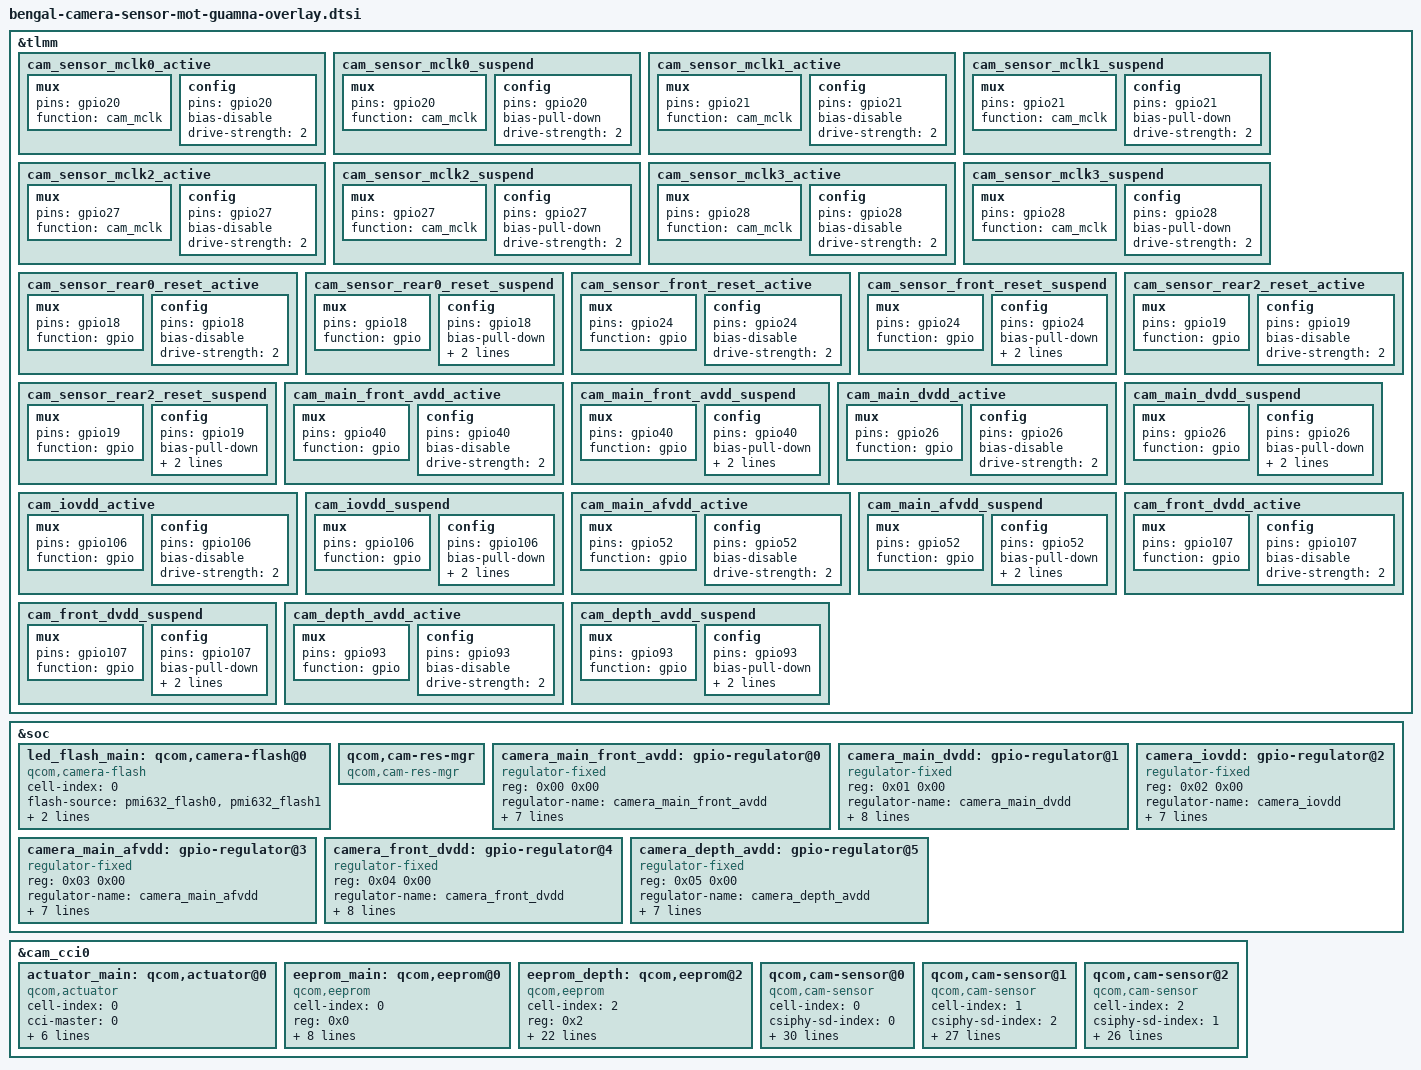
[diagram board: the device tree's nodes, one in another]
#include <dt-bindings/clock/qcom,gcc-bengal.h>

&tlmm {
	cam_sensor_mclk0_active: cam_sensor_mclk0_active {
		/* main mclk*/
		mux {
			pins = "gpio20";
			function = "cam_mclk";
		};

		config {
			pins = "gpio20";
			bias-disable;
			drive-strength = <2>;
		};
	};

	cam_sensor_mclk0_suspend: cam_sensor_mclk0_suspend {
		/* main mclk*/
		mux {
			pins = "gpio20";
			function = "cam_mclk";
		};

		config {
			pins = "gpio20";
			bias-pull-down;
			drive-strength = <2>;
		};
	};

	cam_sensor_mclk1_active: cam_sensor_mclk1_active {
		/* depth mclk*/
		mux {
			pins = "gpio21";
			function = "cam_mclk";
		};

		config {
			pins = "gpio21";
			bias-disable;
			drive-strength = <2>;
		};
	};

	cam_sensor_mclk1_suspend: cam_sensor_mclk1_suspend {
		/* depth mclk*/
		mux {
			pins = "gpio21";
			function = "cam_mclk";
		};

		config {
			pins = "gpio21";
			bias-pull-down;
			drive-strength = <2>;
		};
	};

	cam_sensor_mclk2_active: cam_sensor_mclk2_active {
		/* front mclk*/
		mux {
			pins = "gpio27";
			function = "cam_mclk";
		};

		config {
			pins = "gpio27";
			bias-disable;
			drive-strength = <2>;
		};
	};

	cam_sensor_mclk2_suspend: cam_sensor_mclk2_suspend {
		/* front mclk*/
		mux {
			pins = "gpio27";
			function = "cam_mclk";
		};

		config {
			pins = "gpio27";
			bias-pull-down;
			drive-strength = <2>;
		};
	};

	cam_sensor_mclk3_active: cam_sensor_mclk3_active {
		/* macro mclk*/
		mux {
			pins = "gpio28";
			function = "cam_mclk";
		};

		config {
			pins = "gpio28";
			bias-disable;
			drive-strength = <2>;
		};
	};

	cam_sensor_mclk3_suspend: cam_sensor_mclk3_suspend {
		/* macro mclk*/
		mux {
			pins = "gpio28";
			function = "cam_mclk";
		};

		config {
			pins = "gpio28";
			bias-pull-down;
			drive-strength = <2>;
		};
	};

	cam_sensor_rear0_reset_active: cam_sensor_rear0_reset_active {
		/* main reset*/
		mux {
			pins = "gpio18";
			function = "gpio";
		};

		config {
			pins = "gpio18";
			bias-disable; /* No PULL */
			drive-strength = <2>;
		};
	};

	cam_sensor_rear0_reset_suspend: cam_sensor_rear0_reset_suspend {
		/* main reset*/
		mux {
			pins = "gpio18";
			function = "gpio";
		};

		config {
			pins = "gpio18";
			bias-pull-down; /* PULL DOWN */
			drive-strength = <2>;
			output-low;
		};
	};

	cam_sensor_front_reset_active: cam_sensor_front_reset_active {
		/* front reset*/
		mux {
			pins = "gpio24";
			function = "gpio";
		};

		config {
			pins = "gpio24";
			bias-disable; /* No PULL */
			drive-strength = <2>;
		};
	};

	cam_sensor_front_reset_suspend: cam_sensor_front_reset_suspend {
		/* front reset*/
		mux {
			pins = "gpio24";
			function = "gpio";
		};

		config {
			pins = "gpio24";
			bias-pull-down; /* PULL DOWN */
			drive-strength = <2>;
			output-low;
		};
	};

	cam_sensor_rear2_reset_active: cam_sensor_rear2_reset_active {
		/* depth reset*/
		mux {
			pins = "gpio19";
			function = "gpio";
		};

		config {
			pins = "gpio19";
			bias-disable; /* No PULL */
			drive-strength = <2>;
		};
	};

	cam_sensor_rear2_reset_suspend: cam_sensor_rear2_reset_suspend {
		/* depth reset*/
		mux {
			pins = "gpio19";
			function = "gpio";
		};

		config {
			pins = "gpio19";
			bias-pull-down; /* PULL DOWN */
			drive-strength = <2>;
			output-low;
		};
	};

	cam_main_front_avdd_active: cam_main_front_avdd_active {
		/* MAIN FRONT AVDD EN */
		mux {
			pins = "gpio40";
			function = "gpio";
		};

		config {
			pins = "gpio40";
			bias-disable; /* No PULL */
			drive-strength = <2>; /* 2 MA */
		};
	};

	cam_main_front_avdd_suspend: cam_main_front_avdd_suspend {
		mux {
			pins = "gpio40";
			function = "gpio";
		};

		config {
			pins = "gpio40";
			bias-pull-down; /* PULL DOWN */
			drive-strength = <2>; /* 2 MA */
			output-low;
		};
	};

	cam_main_dvdd_active: cam_main_dvdd_active {
		/* MAIN DVDD EN */
		mux {
			pins = "gpio26";
			function = "gpio";
		};

		config {
			pins = "gpio26";
			bias-disable; /* No PULL */
			drive-strength = <2>; /* 2 MA */
		};
	};

	cam_main_dvdd_suspend: cam_main_dvdd_suspend {
		mux {
			pins = "gpio26";
			function = "gpio";
		};

		config {
			pins = "gpio26";
			bias-pull-down; /* PULL DOWN */
			drive-strength = <2>; /* 2 MA */
			output-low;
		};
	};

	cam_iovdd_active: cam_iovdd_active {
		/* IOVDD EN */
		mux {
			pins = "gpio106";
			function = "gpio";
		};

		config {
			pins = "gpio106";
			bias-disable; /* No PULL */
			drive-strength = <2>; /* 2 MA */
		};
	};

	cam_iovdd_suspend: cam_iovdd_suspend {
		mux {
			pins = "gpio106";
			function = "gpio";
		};

		config {
			pins = "gpio106";
			bias-pull-down; /* PULL DOWN */
			drive-strength = <2>; /* 2 MA */
			output-low;
		};
	};

	cam_main_afvdd_active: cam_main_afvdd_active {
		/* MAIN DVDD EN */
		mux {
			pins = "gpio52";
			function = "gpio";
		};

		config {
			pins = "gpio52";
			bias-disable; /* No PULL */
			drive-strength = <2>; /* 2 MA */
		};
	};

	cam_main_afvdd_suspend: cam_main_afvdd_suspend {
		mux {
			pins = "gpio52";
			function = "gpio";
		};

		config {
			pins = "gpio52";
			bias-pull-down; /* PULL DOWN */
			drive-strength = <2>; /* 2 MA */
			output-low;
		};
	};

	cam_front_dvdd_active: cam_front_dvdd_active {
		/* FRONT DVDD EN */
		mux {
			pins = "gpio107";
			function = "gpio";
		};

		config {
			pins = "gpio107";
			bias-disable; /* No PULL */
			drive-strength = <2>; /* 2 MA */
		};
	};

	cam_front_dvdd_suspend: cam_front_dvdd_suspend {
		mux {
			pins = "gpio107";
			function = "gpio";
		};

		config {
			pins = "gpio107";
			bias-pull-down; /* PULL DOWN */
			drive-strength = <2>; /* 2 MA */
			output-low;
		};
	};

	cam_depth_avdd_active: cam_depth_avdd_active {
		/* DEPTH AVDD EN */
		mux {
			pins = "gpio93";
			function = "gpio";
		};

		config {
			pins = "gpio93";
			bias-disable; /* No PULL */
			drive-strength = <2>; /* 2 MA */
		};
	};

	cam_depth_avdd_suspend: cam_depth_avdd_suspend {
		mux {
			pins = "gpio93";
			function = "gpio";
		};

		config {
			pins = "gpio93";
			bias-pull-down; /* PULL DOWN */
			drive-strength = <2>; /* 2 MA */
			output-low;
		};
	};
};

&soc {
	led_flash_main: qcom,camera-flash@0 {
		cell-index = <0>;
		compatible = "qcom,camera-flash";
		flash-source  = <&pmi632_flash0 &pmi632_flash1>;
		torch-source  = <&pmi632_torch0 &pmi632_torch1>;
		switch-source = <&pmi632_switch0 &pmi632_switch0>;
		status = "ok";
	};

	qcom,cam-res-mgr {
		compatible = "qcom,cam-res-mgr";
		status = "ok";
	};

	camera_main_front_avdd: gpio-regulator@0 {
		compatible = "regulator-fixed";
		reg = <0x00 0x00>;
		regulator-name = "camera_main_front_avdd";
		regulator-min-microvolt = <2800000>;
		regulator-max-microvolt = <2800000>;
		regulator-enable-ramp-delay = <233>;
		enable-active-high;
		gpio = <&tlmm 40 0>;
		pinctrl-names = "default";
		pinctrl-0 = <&cam_main_front_avdd_active>;
		pinctrl-1 = <&cam_main_front_avdd_suspend>;
	};

	camera_main_dvdd: gpio-regulator@1 {
		compatible = "regulator-fixed";
		reg = <0x01 0x00>;
		regulator-name = "camera_main_dvdd";
		regulator-min-microvolt = <1050000>;
		regulator-max-microvolt = <1050000>;
		regulator-enable-ramp-delay = <233>;
		enable-active-high;
		gpio = <&tlmm 26 0>;
		pinctrl-names = "default";
		pinctrl-0 = <&cam_main_dvdd_active>;
		pinctrl-1 = <&cam_main_dvdd_suspend>;
		vin-supply = <&S6A>;
	};

	camera_iovdd: gpio-regulator@2 {
		compatible = "regulator-fixed";
		reg = <0x02 0x00>;
		regulator-name = "camera_iovdd";
		regulator-min-microvolt = <1800000>;
		regulator-max-microvolt = <1800000>;
		regulator-enable-ramp-delay = <233>;
		enable-active-high;
		gpio = <&tlmm 106 0>;
		pinctrl-names = "default";
		pinctrl-0 = <&cam_iovdd_active>;
		pinctrl-1 = <&cam_iovdd_suspend>;
	};

	camera_main_afvdd: gpio-regulator@3 {
		compatible = "regulator-fixed";
		reg = <0x03 0x00>;
		regulator-name = "camera_main_afvdd";
		regulator-min-microvolt = <2800000>;
		regulator-max-microvolt = <2800000>;
		regulator-enable-ramp-delay = <233>;
		enable-active-high;
		gpio = <&tlmm 52 0>;
		pinctrl-names = "default";
		pinctrl-0 = <&cam_main_afvdd_active>;
		pinctrl-1 = <&cam_main_afvdd_suspend>;
	};

	camera_front_dvdd: gpio-regulator@4 {
		compatible = "regulator-fixed";
		reg = <0x04 0x00>;
		regulator-name = "camera_front_dvdd";
		regulator-min-microvolt = <1200000>;
		regulator-max-microvolt = <1200000>;
		regulator-enable-ramp-delay = <233>;
		enable-active-high;
		gpio = <&tlmm 107 0>;
		pinctrl-names = "default";
		pinctrl-0 = <&cam_front_dvdd_active>;
		pinctrl-1 = <&cam_front_dvdd_suspend>;
		vin-supply = <&S6A>;
	};

	camera_depth_avdd: gpio-regulator@5 {
		compatible = "regulator-fixed";
		reg = <0x05 0x00>;
		regulator-name = "camera_depth_avdd";
		regulator-min-microvolt = <2800000>;
		regulator-max-microvolt = <2800000>;
		regulator-enable-ramp-delay = <233>;
		enable-active-high;
		gpio = <&tlmm 93 0>;
		pinctrl-names = "default";
		pinctrl-0 = <&cam_depth_avdd_active>;
		pinctrl-1 = <&cam_depth_avdd_suspend>;
	};
};

&cam_cci0 {
	actuator_main: qcom,actuator@0 {
		cell-index = <0>;
		compatible = "qcom,actuator";
		cci-master = <0>;
		cam_vaf-supply = <&camera_main_afvdd>;
		regulator-names = "cam_vaf";
		rgltr-cntrl-support;
		rgltr-min-voltage = <2800000>;
		rgltr-max-voltage = <2800000>;
		rgltr-load-current = <100000>;
		status = "ok";
	};

	eeprom_main: qcom,eeprom@0 {
		cell-index = <0>;
		reg = <0x0>;
		compatible = "qcom,eeprom";
		cci-master = <0>;
		cam_vaf-supply = <&camera_main_afvdd>;
		cam_vio-supply = <&camera_iovdd>;
		regulator-names = "cam_vaf", "cam_vio";
		rgltr-cntrl-support;
		rgltr-min-voltage = <2800000 1800000>;
		rgltr-max-voltage = <2800000 1800000>;
		rgltr-load-current = <100000 120000>;
		status = "ok";
	};

	eeprom_depth: qcom,eeprom@2 {
		cell-index = <2>;
		reg = <0x2>;
		compatible = "qcom,eeprom";
		cam_vio-supply = <&camera_iovdd>;
		cam_vana-supply = <&camera_depth_avdd>;
		cam_clk-supply = <&gcc_camss_top_gdsc>;
		regulator-names = "cam_vio", "cam_vana", "cam_clk";
		rgltr-cntrl-support;
		rgltr-min-voltage = <1800000 2800000 0>;
		rgltr-max-voltage = <1800000 2800000 0>;
		rgltr-load-current = <120000 80000 0>;
		gpio-no-mux = <0>;
		pinctrl-names = "cam_default", "cam_suspend";
		pinctrl-0 = <&cam_sensor_mclk1_active
				&cam_sensor_rear2_reset_active>;
		pinctrl-1 = <&cam_sensor_mclk1_suspend
				&cam_sensor_rear2_reset_suspend>;
		gpios = <&tlmm 21 0>,
			<&tlmm 19 0>;
		gpio-reset = <1>;
		gpio-req-tbl-num = <0 1>;
		gpio-req-tbl-flags = <1 0>;
		gpio-req-tbl-label = "CAMIF_MCLK1",
					"CAM_PWDN";
		cci-master = <1>;
		status = "ok";
		clocks = <&gcc GCC_CAMSS_MCLK1_CLK>;
		clock-names = "cam_clk";
		clock-cntl-level = "turbo";
		clock-rates = <24000000>;
	};

	 /* main */
	qcom,cam-sensor@0 {
		cell-index = <0>;
		compatible = "qcom,cam-sensor";
		csiphy-sd-index = <0>;
		sensor-position-roll = <90>;
		sensor-position-pitch = <0>;
		sensor-position-yaw = <180>;
		actuator-src = <&actuator_main>;
		led-flash-src = <&led_flash_main>;
		eeprom-src = <&eeprom_main>;
		cam_vio-supply = <&camera_iovdd>;
		cam_vana-supply = <&camera_main_front_avdd>;
		cam_vdig-supply = <&camera_main_dvdd>;
		cam_clk-supply = <&gcc_camss_top_gdsc>;
		regulator-names = "cam_vio", "cam_vana", "cam_vdig",
			"cam_clk";
		rgltr-cntrl-support;
		rgltr-min-voltage = <1800000 2800000 1050000 0>;
		rgltr-max-voltage = <1800000 2800000 1050000 0>;
		rgltr-load-current = <120000 80000 1200000 0>;
		gpio-no-mux = <0>;
		pinctrl-names = "cam_default", "cam_suspend";
		pinctrl-0 = <&cam_sensor_mclk0_active
				&cam_sensor_rear0_reset_active>;
		pinctrl-1 = <&cam_sensor_mclk0_suspend
				&cam_sensor_rear0_reset_suspend>;
		gpios = <&tlmm 20 0>,
			<&tlmm 18 0>;
		gpio-reset = <1>;
		gpio-req-tbl-num = <0 1>;
		gpio-req-tbl-flags = <1 0>;
		gpio-req-tbl-label = "CAMIF_MCLK0",
					"CAM_RESET0";
		cci-master = <0>;
		status = "ok";
		clocks = <&gcc GCC_CAMSS_MCLK0_CLK>;
		clock-names = "cam_clk";
		clock-cntl-level = "turbo";
		clock-rates = <24000000>;
	};

	 /* front */
	qcom,cam-sensor@1 {
		cell-index = <1>;
		compatible = "qcom,cam-sensor";
		csiphy-sd-index = <2>;
		sensor-position-roll = <270>;
		sensor-position-pitch = <0>;
		sensor-position-yaw = <0>;
		//eeprom-src = <&eeprom_front>;
		cam_vio-supply = <&camera_iovdd>;
		cam_vana-supply = <&camera_main_front_avdd>;
		cam_vdig-supply = <&camera_front_dvdd>;
		cam_clk-supply = <&gcc_camss_top_gdsc>;
		regulator-names = "cam_vio", "cam_vana", "cam_vdig",
			"cam_clk";
		rgltr-cntrl-support;
		rgltr-min-voltage = <1800000 2800000 1200000 0>;
		rgltr-max-voltage = <1800000 2800000 1200000 0>;
		rgltr-load-current = <120000 80000 1200000 0>;
		gpio-no-mux = <0>;
		pinctrl-names = "cam_default", "cam_suspend";
		pinctrl-0 = <&cam_sensor_mclk2_active
				&cam_sensor_front_reset_active>;
		pinctrl-1 = <&cam_sensor_mclk2_suspend
				&cam_sensor_front_reset_suspend>;
		gpios = <&tlmm 27 0>,
			<&tlmm 24 0>;
		gpio-reset = <1>;
		gpio-req-tbl-num = <0 1>;
		gpio-req-tbl-flags = <1 0>;
		gpio-req-tbl-label = "CAMIF_MCLK2",
					"CAM_RESET2";
		cci-master = <1>;
		status = "ok";
		clocks = <&gcc GCC_CAMSS_MCLK2_CLK>;
		clock-names = "cam_clk";
		clock-cntl-level = "turbo";
		clock-rates = <24000000>;
	};

	 /* ov02b1b */
	qcom,cam-sensor@2 {
		cell-index = <2>;
		compatible = "qcom,cam-sensor";
		csiphy-sd-index = <1>;
		sensor-position-roll = <90>;
		sensor-position-pitch = <0>;
		sensor-position-yaw = <180>;
		eeprom-src = <&eeprom_depth>;
		cam_vio-supply = <&camera_iovdd>;
		cam_vana-supply = <&camera_depth_avdd>;
		cam_clk-supply = <&gcc_camss_top_gdsc>;
		regulator-names = "cam_vio", "cam_vana", "cam_clk";
		rgltr-cntrl-support;
		rgltr-min-voltage = <1800000 2800000 0>;
		rgltr-max-voltage = <1800000 2800000 0>;
		rgltr-load-current = <120000 80000 0>;
		gpio-no-mux = <0>;
		pinctrl-names = "cam_default", "cam_suspend";
		pinctrl-0 = <&cam_sensor_mclk1_active
				&cam_sensor_rear2_reset_active>;
		pinctrl-1 = <&cam_sensor_mclk1_suspend
				&cam_sensor_rear2_reset_suspend>;
		gpios = <&tlmm 21 0>,
			<&tlmm 19 0>;
		gpio-reset = <1>;
		gpio-req-tbl-num = <0 1>;
		gpio-req-tbl-flags = <1 0>;
		gpio-req-tbl-label = "CAMIF_MCLK1",
					"CAM_PWDN";
		cci-master = <1>;
		status = "ok";
		clocks = <&gcc GCC_CAMSS_MCLK1_CLK>;
		clock-names = "cam_clk";
		clock-cntl-level = "turbo";
		clock-rates = <24000000>;
	};
};
